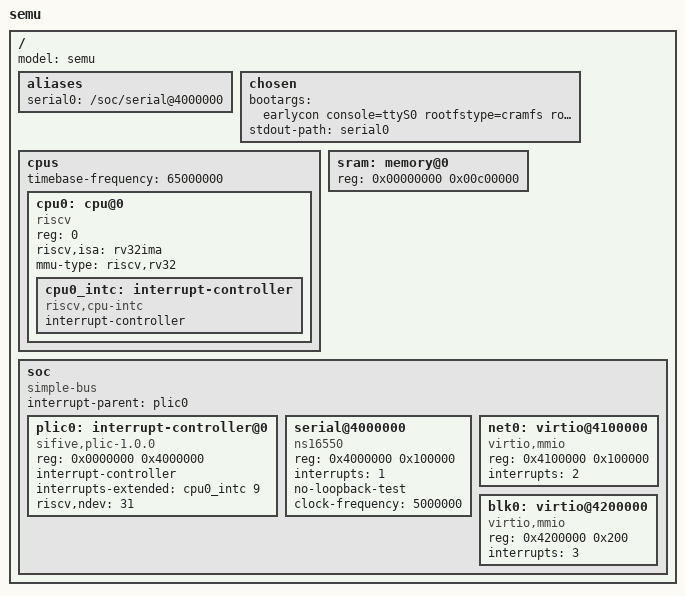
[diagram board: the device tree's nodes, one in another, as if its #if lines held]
/dts-v1/;

/ {
    #address-cells = <1>;
    #size-cells = <1>;
    model = "semu";

    aliases {
	serial0 = "/soc/serial@4000000";
    };

    chosen {
	bootargs = "earlycon console=ttyS0 rootfstype=cramfs root=mtd0 phram.phram=mtd0,0x0c00000,0x400000";
	stdout-path = "serial0";
	//linux,initrd-start = <0x0c00000>; /* 16MiB - 4MiB */
	//linux,initrd-end =   <0x0ffffff>; /* 16MiB - 1 */
    };

    cpus {
	#address-cells = <1>;
	#size-cells = <0>;
	timebase-frequency = <65000000>;
	cpu0: cpu@0 {
	    device_type = "cpu";
	    compatible = "riscv";
	    reg = <0>;
	    riscv,isa = "rv32ima";
	    mmu-type = "riscv,rv32";
	    cpu0_intc: interrupt-controller {
		#interrupt-cells = <1>;
		interrupt-controller;
		compatible = "riscv,cpu-intc";
	    };
	};
    };


    sram: memory@0 {
	device_type = "memory";
	reg = <0x00000000 0x00c00000>;
	reg-names = "sram0";
    };

    
    soc {
	#address-cells = <1>;
	#size-cells = <1>;
	compatible = "simple-bus";
	ranges = <0x0 0xF0000000 0x10000000>;
	interrupt-parent = <&plic0>;

	plic0: interrupt-controller@0 {
	    #interrupt-cells = <1>;
	    #address-cells = <0>;
	    compatible = "sifive,plic-1.0.0";
	    reg = <0x0000000 0x4000000>;
	    interrupt-controller;
	    interrupts-extended = <&cpu0_intc 9>;
	    riscv,ndev = <31>;
	};

	serial@4000000 {
	    compatible = "ns16550";
	    reg = <0x4000000 0x100000>;
	    interrupts = <1>;
	    no-loopback-test;
	    clock-frequency = <5000000>; /* the baudrate divisor is ignored */
	};

/*        flash@1c00000 {
    	    compatible = "mtd-ram";
  	    reg = <0x01c00000 0x01400000>;
	    bank-width = <4>;
    	};*/


#if SEMU_FEATURE_VIRTIONET
	net0: virtio@4100000 {
	    compatible = "virtio,mmio";
	    reg = <0x4100000 0x100000>;
	    interrupts = <2>;
	};
#endif

#if SEMU_FEATURE_VIRTIOBLK
	blk0: virtio@4200000 {
	    compatible = "virtio,mmio";
	    reg = <0x4200000 0x200>;
	    interrupts = <3>;
	};
#endif
    };
};
